# PIC32MK0512GPL100 register map
Vendor: Microchip
Registers are 32-bit, read-write, no defined reset value unless marked. A register's access mark holds for its fields unless they carry their own. Addresses are absolute, and some are shared; only a register's first bit layout is shown; [hi:lo] are bit positions; {n}, {i} and the like mark numbered series; 'fields as' and 'values as' point back to an identical list.

## RPORx
{0x1F801600+4i} RPA{i}R reset 0x0 (i=0..4)
  [4:0] RPA{i}R
0x1F80161C RPA7R reset 0x0
  [4:0] RPA7R
0x1F801620 RPA8R reset 0x0
  [4:0] RPA8R
0x1F80162C RPA11R reset 0x0
  [4:0] RPA11R
0x1F801630 RPA12R reset 0x0
  [4:0] RPA12R
0x1F801638 RPA14R reset 0x0
  [4:0] RPA14R
0x1F80163C RPA15R reset 0x0
  [4:0] RPA15R
{0x1F801640+4i} RPB{i}R reset 0x0 (i=0..7)
  [4:0] RPB{i}R
{0x1F801640+4i} RPB{i}R reset 0x0 (i=9..15)
  [4:0] RPB{i}R
{0x1F801680+4i} RPC{i}R reset 0x0 (i=0..2)
  [4:0] RPC{i}R
{0x1F801680+4i} RPC{i}R reset 0x0 (i=4..10)
  [4:0] RPC{i}R
0x1F8016B0 RPC12R reset 0x0
  [4:0] RPC12R
0x1F8016BC RPC15R reset 0x0
  [4:0] RPC15R
{0x1F8016C0+4i} RPD{i}R reset 0x0 (i=3..6)
  [4:0] RPD{i}R
0x1F801700 RPE0R reset 0x0
  [4:0] RPE0R
0x1F801704 RPE1R reset 0x0
  [4:0] RPE1R
0x1F801738 RPE14R reset 0x0
  [4:0] RPE14R
0x1F80173C RPE15R reset 0x0
  [4:0] RPE15R
0x1F801740 RPF0R reset 0x0
  [4:0] RPF0R
0x1F801744 RPF1R reset 0x0
  [4:0] RPF1R
0x1F801780 RPG0R reset 0x0
  [4:0] RPG0R
0x1F801784 RPG1R reset 0x0
  [4:0] RPG1R
{0x1F801780+4i} RPG{i}R reset 0x0 (i=6..9)
  [4:0] RPG{i}R
0x1F8017B0 RPG12R reset 0x0
  [4:0] RPG12R

## HLVD
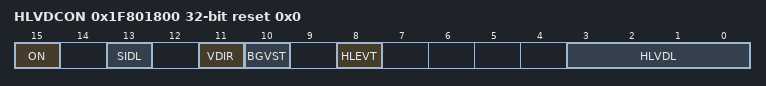
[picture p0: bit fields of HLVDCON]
0x1F801800 HLVDCON reset 0x0
  [15] ON, [13] SIDL, [11] VDIR, [10] BGVST, [8] HLEVT, [3:0] HLVDL

## dma_bvci
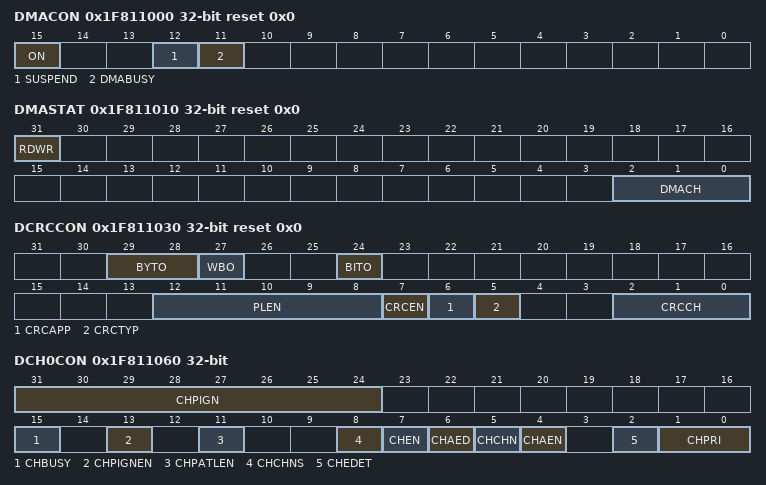
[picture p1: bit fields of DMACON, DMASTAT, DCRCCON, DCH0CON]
0x1F811000 DMACON reset 0x0
  [15] ON, [12] SUSPEND, [11] DMABUSY
0x1F811010 DMASTAT ro reset 0x0
  [31] RDWR, [2:0] DMACH
0x1F811020 DMAADDR ro reset 0x0
0x1F811030 DCRCCON reset 0x0
  [29:28] BYTO, [27] WBO, [24] BITO, [12:8] PLEN, [7] CRCEN, [6] CRCAPP, [5] CRCTYP, [2:0] CRCCH
0x1F811040 DCRCDATA reset 0x0
0x1F811050 DCRCXOR reset 0x0
0x1F811060 DCH0CON — (power-on value xxxxxxxx--------0-0-0--00000-000)
  [31:24] CHPIGN, [15] CHBUSY, [13] CHPIGNEN, [11] CHPATLEN, [8] CHCHNS, [7] CHEN, [6] CHAED, [5] CHCHN, [4] CHAEN, [2] CHEDET ro, [1:0] CHPRI
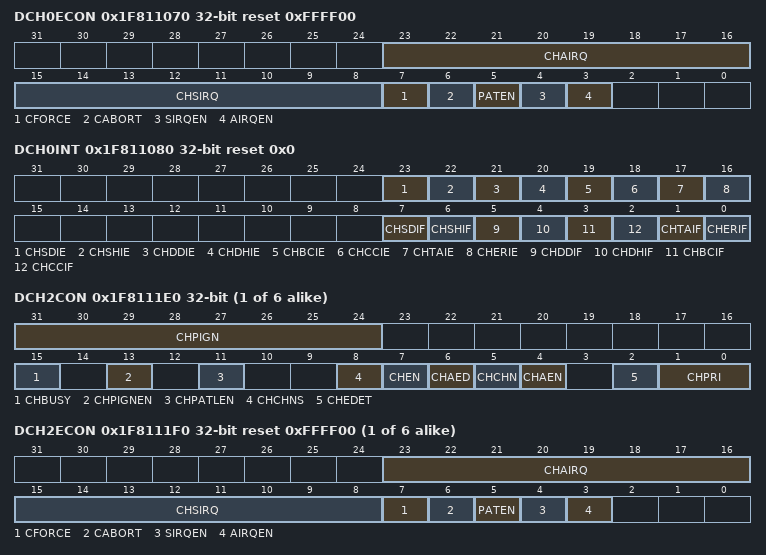
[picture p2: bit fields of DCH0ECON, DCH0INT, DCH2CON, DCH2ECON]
0x1F811070 DCH0ECON reset 0xFFFF00
  [23:16] CHAIRQ, [15:8] CHSIRQ, [7] CFORCE, [6] CABORT, [5] PATEN, [4] SIRQEN, [3] AIRQEN
0x1F811080 DCH0INT reset 0x0
  [23] CHSDIE, [22] CHSHIE, [21] CHDDIE, [20] CHDHIE, [19] CHBCIE, [18] CHCCIE, [17] CHTAIE, [16] CHERIE, [7] CHSDIF, [6] CHSHIF, [5] CHDDIF, [4] CHDHIF, [3] CHBCIF, [2] CHCCIF, [1] CHTAIF, [0] CHERIF
0x1F811090 DCH0SSA — (power-on value xxxxxxxxxxxxxxxxxxxxxxxxxxxxxxxx)
  [31:0] CHSSA
0x1F8110A0 DCH0DSA — (power-on value xxxxxxxxxxxxxxxxxxxxxxxxxxxxxxxx)
  [31:0] CHDSA
0x1F8110B0 DCH0SSIZ — (power-on value ----------------xxxxxxxxxxxxxxxx)
  [15:0] CHSSIZ
0x1F8110C0 DCH0DSIZ — (power-on value ----------------xxxxxxxxxxxxxxxx)
  [15:0] CHDSIZ
0x1F8110D0 DCH0SPTR reset 0x0
  [15:0] CHSPTR
0x1F8110E0 DCH0DPTR reset 0x0
  [15:0] CHDPTR
0x1F8110F0 DCH0CSIZ — (power-on value ----------------xxxxxxxxxxxxxxxx)
  [15:0] CHCSIZ
0x1F811100 DCH0CPTR reset 0x0
  [15:0] CHCPTR
0x1F811110 DCH0DAT — (power-on value ----------------xxxxxxxxxxxxxxxx)
  [15:0] CHPDAT
{0x1F811060+0xC0*i} DCH{i}CON (i=2..7) — (power-on value xxxxxxxx--------0-0-0--00000-000)
  fields as DCH0CON
{0x1F811070+0xC0*i} DCH{i}ECON reset 0xFFFF00 (i=2..7)
  fields as DCH0ECON
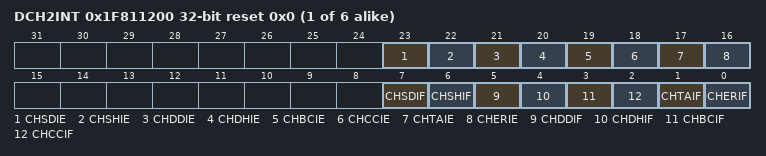
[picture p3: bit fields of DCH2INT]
{0x1F811080+0xC0*i} DCH{i}INT reset 0x0 (i=2..7)
  fields as DCH0INT
{0x1F811090+0xC0*i} DCH{i}SSA (i=2..7) — (power-on value xxxxxxxxxxxxxxxxxxxxxxxxxxxxxxxx)
  [31:0] CHSSA
{0x1F8110A0+0xC0*i} DCH{i}DSA (i=2..7) — (power-on value xxxxxxxxxxxxxxxxxxxxxxxxxxxxxxxx)
  [31:0] CHDSA
{0x1F8110B0+0xC0*i} DCH{i}SSIZ (i=2..7) — (power-on value ----------------xxxxxxxxxxxxxxxx)
  [15:0] CHSSIZ
{0x1F8110C0+0xC0*i} DCH{i}DSIZ (i=2..7) — (power-on value ----------------xxxxxxxxxxxxxxxx)
  [15:0] CHDSIZ
{0x1F8110D0+0xC0*i} DCH{i}SPTR reset 0x0 (i=2..7)
  [15:0] CHSPTR
{0x1F8110E0+0xC0*i} DCH{i}DPTR reset 0x0 (i=2..7)
  [15:0] CHDPTR
{0x1F8110F0+0xC0*i} DCH{i}CSIZ (i=2..7) — (power-on value ----------------xxxxxxxxxxxxxxxx)
  [15:0] CHCSIZ
{0x1F811100+0xC0*i} DCH{i}CPTR reset 0x0 (i=2..7)
  [15:0] CHCPTR
{0x1F811110+0xC0*i} DCH{i}DAT (i=2..7) — (power-on value ----------------xxxxxxxxxxxxxxxx)
  [15:0] CHPDAT
